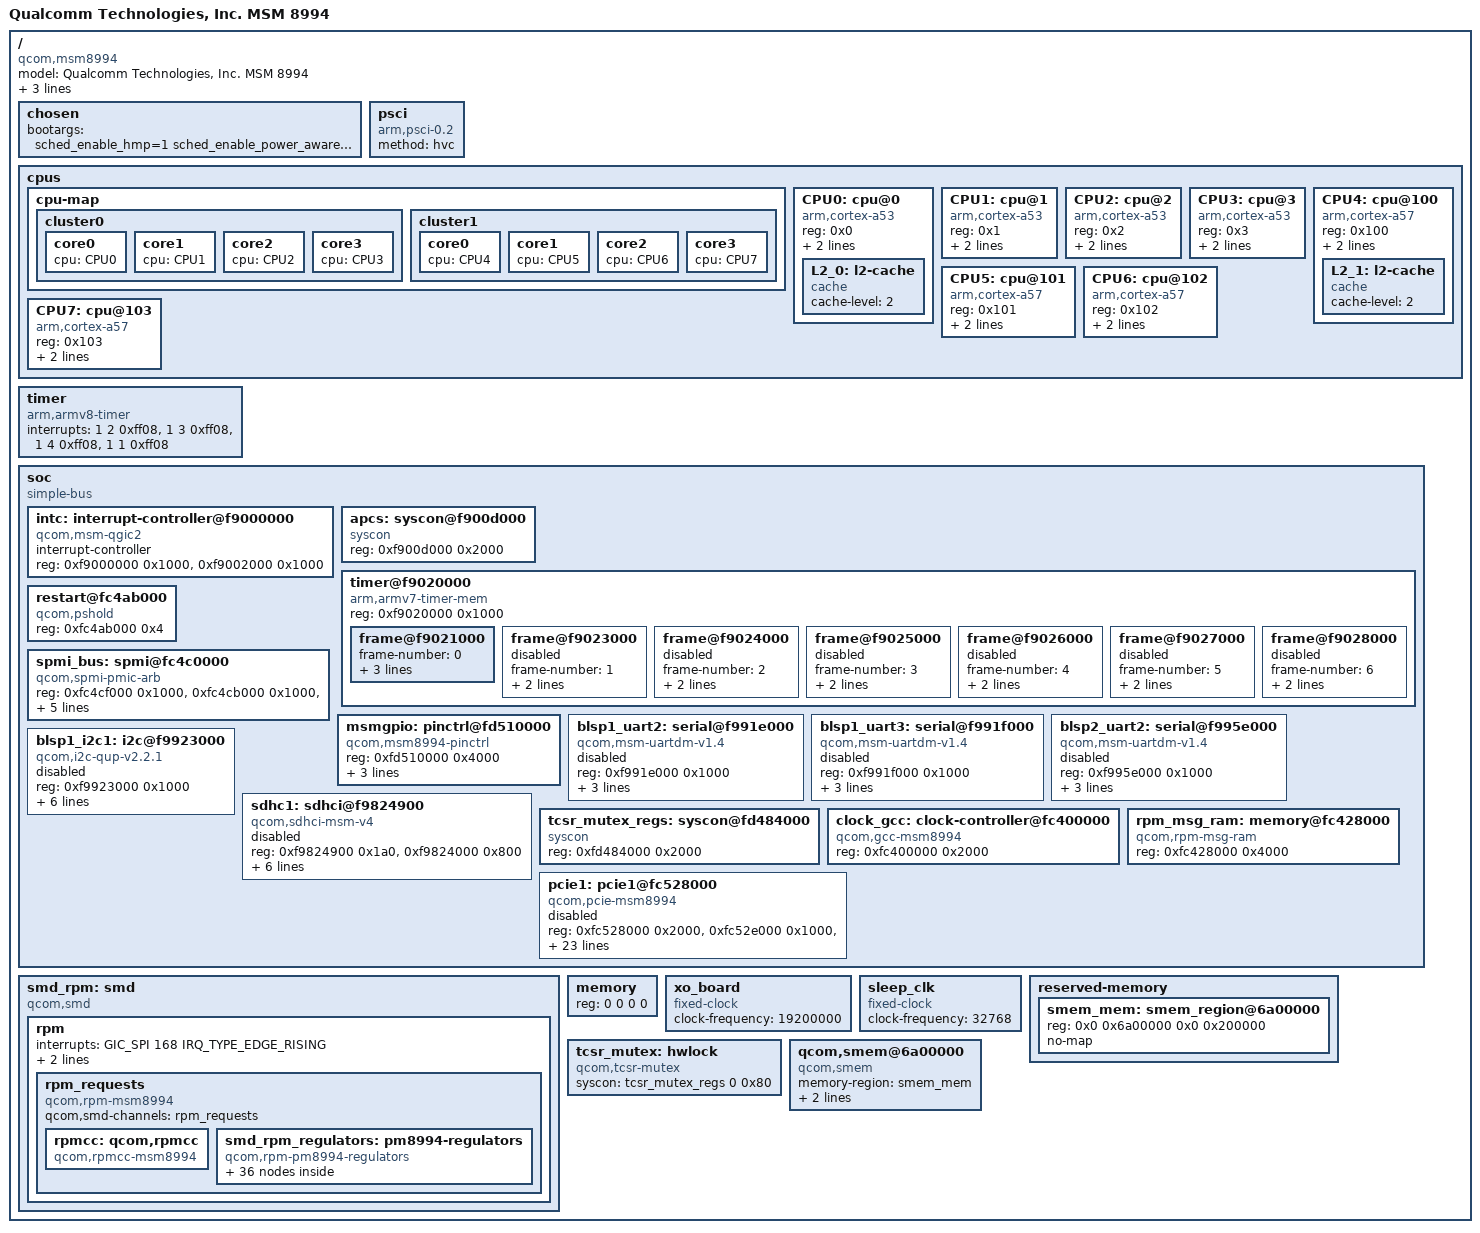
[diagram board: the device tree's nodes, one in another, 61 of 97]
/* Copyright (c) 2013-2016, The Linux Foundation. All rights reserved.
 *
 * This program is free software; you can redistribute it and/or modify
 * it under the terms of the GNU General Public License version 2 and
 * only version 2 as published by the Free Software Foundation.
 *
 * This program is distributed in the hope that it will be useful,
 * but WITHOUT ANY WARRANTY; without even the implied warranty of
 * MERCHANTABILITY or FITNESS FOR A PARTICULAR PURPOSE.  See the
 * GNU General Public License for more details.
 */

#include <dt-bindings/interrupt-controller/arm-gic.h>
#include <dt-bindings/clock/qcom,gcc-msm8994.h>
#include <dt-bindings/clock/qcom,rpmcc.h>

/ {
	model = "Qualcomm Technologies, Inc. MSM 8994";
	compatible = "qcom,msm8994";
	// msm-id and pmic-id are required by bootloader for
	// proper selection of dt blob
	qcom,msm-id = <207 0x20000>;
	qcom,pmic-id = <0x10009 0x1000A 0x0 0x0>;
	interrupt-parent = <&intc>;

	#address-cells = <2>;
	#size-cells = <2>;

	chosen {
		bootargs = "sched_enable_hmp=1 sched_enable_power_aware=1";
	};

	psci {
		compatible	= "arm,psci-0.2";
		method		= "hvc";
	};

	cpus {
		#address-cells = <1>;
		#size-cells = <0>;
		cpu-map {
			cluster0 {
				core0 {
					cpu = <&CPU0>;
				};
				core1 {
					cpu = <&CPU1>;
				};
				core2 {
					cpu = <&CPU2>;
				};
				core3 {
					cpu = <&CPU3>;
				};
			};
			cluster1 {
				core0 {
					cpu = <&CPU4>;
				};
				core1 {
					cpu = <&CPU5>;
				};
				core2 {
					cpu = <&CPU6>;
				};
				core3 {
					cpu = <&CPU7>;
				};
			};
		};

		CPU0: cpu@0 {
			device_type = "cpu";
			compatible = "arm,cortex-a53";
			reg = <0x0>;
			enable-method = "psci";
			next-level-cache = <&L2_0>;
			L2_0: l2-cache {
				compatible = "cache";
				cache-level = <2>;
			};
		};
		CPU1: cpu@1 {
			device_type = "cpu";
			compatible = "arm,cortex-a53";
			reg = <0x1>;
			enable-method = "psci";
			next-level-cache = <&L2_0>;
		};
		CPU2: cpu@2 {
			device_type = "cpu";
			compatible = "arm,cortex-a53";
			reg = <0x2>;
			enable-method = "psci";
			next-level-cache = <&L2_0>;
		};
		CPU3: cpu@3 {
			device_type = "cpu";
			compatible = "arm,cortex-a53";
			reg = <0x3>;
			enable-method = "psci";
			next-level-cache = <&L2_0>;
		};
		CPU4: cpu@100 {
			device_type = "cpu";
			compatible = "arm,cortex-a57";
			reg = <0x100>;
			enable-method = "psci";
			next-level-cache = <&L2_1>;
			L2_1: l2-cache {
				compatible = "cache";
				cache-level = <2>;
			};
		};
		CPU5: cpu@101 {
			device_type = "cpu";
			compatible = "arm,cortex-a57";
			reg = <0x101>;
			enable-method = "psci";
			next-level-cache = <&L2_1>;
		};
		CPU6: cpu@102 {
			device_type = "cpu";
			compatible = "arm,cortex-a57";
			reg = <0x102>;
			enable-method = "psci";
			next-level-cache = <&L2_1>;
		};
		CPU7: cpu@103 {
			device_type = "cpu";
			compatible = "arm,cortex-a57";
			reg = <0x103>;
			enable-method = "psci";
			next-level-cache = <&L2_1>;
		};
	};

	timer {
		compatible = "arm,armv8-timer";
		interrupts = <1 2 0xff08>,
			     <1 3 0xff08>,
			     <1 4 0xff08>,
			     <1 1 0xff08>;
	};

	soc: soc {

		#address-cells = <1>;
		#size-cells = <1>;
		ranges = <0 0 0 0xffffffff>;
		compatible = "simple-bus";

		intc: interrupt-controller@f9000000 {
			compatible = "qcom,msm-qgic2";
			interrupt-controller;
			#interrupt-cells = <3>;
			reg = <0xf9000000 0x1000>,
				  <0xf9002000 0x1000>;
		};

		apcs: syscon@f900d000 {
			compatible = "syscon";
			reg = <0xf900d000 0x2000>;
		};

		timer@f9020000 {
			#address-cells = <1>;
			#size-cells = <1>;
			ranges;
			compatible = "arm,armv7-timer-mem";
			reg = <0xf9020000 0x1000>;

			frame@f9021000 {
				frame-number = <0>;
				interrupts = <GIC_SPI 9 IRQ_TYPE_LEVEL_HIGH>,
					     <GIC_SPI 8 IRQ_TYPE_LEVEL_HIGH>;
				reg = <0xf9021000 0x1000>,
				      <0xf9022000 0x1000>;
			};

			frame@f9023000 {
				frame-number = <1>;
				interrupts = <GIC_SPI 10 IRQ_TYPE_LEVEL_HIGH>;
				reg = <0xf9023000 0x1000>;
				status = "disabled";
			};

			frame@f9024000 {
				frame-number = <2>;
				interrupts = <GIC_SPI 11 IRQ_TYPE_LEVEL_HIGH>;
				reg = <0xf9024000 0x1000>;
				status = "disabled";
			};

			frame@f9025000 {
				frame-number = <3>;
				interrupts = <GIC_SPI 12 IRQ_TYPE_LEVEL_HIGH>;
				reg = <0xf9025000 0x1000>;
				status = "disabled";
			};

			frame@f9026000 {
				frame-number = <4>;
				interrupts = <GIC_SPI 13 IRQ_TYPE_LEVEL_HIGH>;
				reg = <0xf9026000 0x1000>;
				status = "disabled";
			};

			frame@f9027000 {
				frame-number = <5>;
				interrupts = <GIC_SPI 14 IRQ_TYPE_LEVEL_HIGH>;
				reg = <0xf9027000 0x1000>;
				status = "disabled";
			};

			frame@f9028000 {
				frame-number = <6>;
				interrupts = <GIC_SPI 15 IRQ_TYPE_LEVEL_HIGH>;
				reg = <0xf9028000 0x1000>;
				status = "disabled";
			};
		};

		restart@fc4ab000 {
			compatible = "qcom,pshold";
			reg = <0xfc4ab000 0x4>;
		};

		spmi_bus: spmi@fc4c0000 {
			compatible = "qcom,spmi-pmic-arb";
			reg-names = "core", "intr", "cnfg";
			reg = <0xfc4cf000 0x1000>,
				<0xfc4cb000 0x1000>,
				<0xfc4ca000 0x1000>;

			interrupt-names = "periph_irq";
			interrupts = <GIC_SPI 190 IRQ_TYPE_LEVEL_HIGH>;

			qcom,ee = <0>;
			qcom,channel = <0>;

			#address-cells = <2>;
			#size-cells = <0>;

			interrupt-controller;
			#interrupt-cells = <4>;
		};

		msmgpio: pinctrl@fd510000 {
			compatible = "qcom,msm8994-pinctrl";
			reg = <0xfd510000 0x4000>;
			interrupts = <GIC_SPI 208 IRQ_TYPE_LEVEL_HIGH>;
			gpio-controller;
			#gpio-cells = <2>;
			interrupt-controller;
			#interrupt-cells = <2>;
		};

		blsp1_uart2: serial@f991e000 {
			compatible = "qcom,msm-uartdm-v1.4", "qcom,msm-uartdm";
			reg = <0xf991e000 0x1000>;
			interrupts = <GIC_SPI 108 IRQ_TYPE_LEVEL_HIGH>;
			status = "disabled";
			clock-names = "core", "iface";
			clocks = <&clock_gcc GCC_BLSP1_UART2_APPS_CLK>,
				 <&clock_gcc GCC_BLSP1_AHB_CLK>;
		};

		blsp1_uart3: serial@f991f000 {
			compatible = "qcom,msm-uartdm-v1.4", "qcom,msm-uartdm";
			reg = <0xf991f000 0x1000>;
			interrupts = <GIC_SPI 109 IRQ_TYPE_LEVEL_HIGH>;
			status = "disabled";
			clock-names = "core", "iface";
			clocks = <&clock_gcc GCC_BLSP1_UART3_APPS_CLK>,
				 <&clock_gcc GCC_BLSP1_AHB_CLK>;
		};

		blsp2_uart2: serial@f995e000 {
			compatible = "qcom,msm-uartdm-v1.4", "qcom,msm-uartdm";
			reg = <0xf995e000 0x1000>;
			interrupts = <GIC_SPI 114 IRQ_TYPE_LEVEL_HIGH>;
			status = "disabled";
			clock-names = "core", "iface";
			clocks = <&clock_gcc GCC_BLSP2_UART2_APPS_CLK>,
				 <&clock_gcc GCC_BLSP2_AHB_CLK>;
		};

		blsp1_i2c1: i2c@f9923000 {
			compatible = "qcom,i2c-qup-v2.2.1";
			reg = <0xf9923000 0x1000>;
			interrupts = <GIC_SPI 95 IRQ_TYPE_LEVEL_HIGH>;
			clocks = <&clock_gcc GCC_BLSP1_AHB_CLK>,
				 <&clock_gcc GCC_BLSP1_QUP1_I2C_APPS_CLK>;
			clock-names = "iface", "core";
			pinctrl-names = "default", "sleep";
			pinctrl-0 = <&i2c1_default>;
			pinctrl-1 = <&i2c1_sleep>;
			clock-frequency = <400000>;
			#address-cells = <1>;
			#size-cells = <0>;
			status = "disabled";
		};

		sdhc1: sdhci@f9824900 {
			status = "disabled";
			compatible = "qcom,sdhci-msm-v4";
			reg = <0xf9824900 0x1a0>, <0xf9824000 0x800>;
			reg-names = "hc_mem", "core_mem";

			interrupts = <0 123 IRQ_TYPE_LEVEL_HIGH>,
				      <0 138 IRQ_TYPE_LEVEL_HIGH>;
			interrupt-names = "hc_irq", "pwr_irq";

			clock-names = "iface", "core", "xo";
			clocks = <&clock_gcc GCC_SDCC1_AHB_CLK>,
			<&clock_gcc GCC_SDCC1_APPS_CLK>,
			<&xo_board>;
			bus-width = <4>;
			non-removable;
		};

		tcsr_mutex_regs: syscon@fd484000 {
			compatible = "syscon";
			reg = <0xfd484000 0x2000>;
		};

		clock_gcc: clock-controller@fc400000 {
			compatible = "qcom,gcc-msm8994";
			#clock-cells = <1>;
			#reset-cells = <1>;
			#power-domain-cells = <1>;
			reg = <0xfc400000 0x2000>;
		};

		rpm_msg_ram: memory@fc428000 {
			compatible = "qcom,rpm-msg-ram";
			reg = <0xfc428000 0x4000>;
		};

		pcie1: pcie1@fc528000 {
			compatible = "qcom,pcie-msm8994", "snps,dc-pcie";
			reg = <0xfc528000 0x2000>,
				<0xfc52e000 0x1000>,
				<0xf8800000 0xf1d>,
				<0xf8800f20 0xa8>,
		    	<0xf8801000 0x7f000>;
			reg-names = "parf", "altphy", "dbi", "elbi","config";

			bus-range = <0x00 0xff>;
			num-lanes = <1>;

			#address-cells = <3>;
			#size-cells = <2>;
			ranges = <0x01000000 0x0 0xf8880000 0xf8880000 0x0 0x80000>,
				<0x02000000 0x0 0xf8900000 0xf8900000 0x0 0x700000>;
			interrupts = <GIC_SPI 271 IRQ_TYPE_LEVEL_HIGH>;
			interrupt-names = "msi";
			#interrupt-cells = <1>;
			interrupt-map-mask = <0 0 0 0x7>;
			interrupt-map = <0 0 0 1 &intc 0 272 IRQ_TYPE_LEVEL_HIGH>, /* int_a */
					<0 0 0 2 &intc 0 273 IRQ_TYPE_LEVEL_HIGH>, /* int_b */
					<0 0 0 3 &intc 0 274 IRQ_TYPE_LEVEL_HIGH>, /* int_c */
					<0 0 0 4 &intc 0 275 IRQ_TYPE_LEVEL_HIGH>; /* int_d */

			pinctrl-names = "default";
			pinctrl-0 = <&pcie1_clkreq_default &pcie1_perst_default &pcie1_wake_default>;

			vdda-phy-supply = <&pm8994_l28>;
			vdda-pll-supply = <&pm8994_l12>;

			linux,pci-domain = <1>;

			clocks = <&clock_gcc GCC_PCIE_1_PIPE_CLK>,
				<&rpmcc RPM_SMD_LN_BB_CLK>,
				<&clock_gcc GCC_PCIE_1_AUX_CLK>,
				<&clock_gcc GCC_PCIE_1_CFG_AHB_CLK>,
				<&clock_gcc GCC_PCIE_1_MSTR_AXI_CLK>,
				<&clock_gcc GCC_PCIE_1_PHY_LDO_EN_CLK>;

			clock-names = "pipe_clk",
				"ref_clk_src",
				"aux_clk",
				"cfg_ahb_clk",
				"mstr_axi_clk",
				"phy_ldo_clk";

			resets = <&clock_gcc GCC_PCIE_PHY_1_PHY_BCR>;
			reset-names = "phy_reset";
			status = "disabled";
		};
	};

	smd_rpm: smd {
		compatible = "qcom,smd";
		rpm {
			interrupts = <GIC_SPI 168 IRQ_TYPE_EDGE_RISING>;
			qcom,ipc = <&apcs 8 0>;
			qcom,smd-edge = <15>;
			
			rpm_requests {
				compatible = "qcom,rpm-msm8994";
				qcom,smd-channels = "rpm_requests";

				rpmcc: qcom,rpmcc {
					compatible = "qcom,rpmcc-msm8994";
					#clock-cells = <1>;
				};

				smd_rpm_regulators: pm8994-regulators {
					compatible = "qcom,rpm-pm8994-regulators";

					pm8994_s1: s1 {};
					pm8994_s2: s2 {};
					pm8994_s3: s3 {};
					pm8994_s4: s4 {};
					pm8994_s5: s5 {};
					pm8994_s7: s7 {};

					pm8994_l1: l1 {};
					pm8994_l2: l2 {};
					pm8994_l3: l3 {};
					pm8994_l4: l4 {};
					pm8994_l6: l6 {};
					pm8994_l8: l8 {};
					pm8994_l9: l9 {};
					pm8994_l10: l10 {};
					pm8994_l11: l11 {};
					pm8994_l12: l12 {};
					pm8994_l13: l13 {};
					pm8994_l14: l14 {};
					pm8994_l15: l15 {};
					pm8994_l16: l16 {};
					pm8994_l17: l17 {};
					pm8994_l18: l18 {};
					pm8994_l19: l19 {};
					pm8994_l20: l20 {};
					pm8994_l21: l21 {};
					pm8994_l22: l22 {};
					pm8994_l23: l23 {};
					pm8994_l24: l24 {};
					pm8994_l25: l25 {};
					pm8994_l26: l26 {};
					pm8994_l27: l27 {};
					pm8994_l28: l28 {};
					pm8994_l29: l29 {};
					pm8994_l30: l30 {};
					pm8994_l31: l31 {};
					pm8994_l32: l32 {};
				};
			};
		};
	};

	memory {
		device_type = "memory";
		// We expect the bootloader to fill in the reg
		reg = <0 0 0 0>;
	};

	xo_board: xo_board {
		compatible = "fixed-clock";
		#clock-cells = <0>;
		clock-frequency = <19200000>;
	};

	sleep_clk: sleep_clk {
		compatible = "fixed-clock";
		#clock-cells = <0>;
		clock-frequency = <32768>;
	};

	reserved-memory {
		#address-cells = <2>;
		#size-cells = <2>;
		ranges;

		smem_mem: smem_region@6a00000 {
			reg = <0x0 0x6a00000 0x0 0x200000>;
			no-map;
		};
	};

	tcsr_mutex: hwlock {
		compatible = "qcom,tcsr-mutex";
		syscon = <&tcsr_mutex_regs 0 0x80>;
		#hwlock-cells = <1>;
	};

	qcom,smem@6a00000 {
		compatible = "qcom,smem";
		memory-region = <&smem_mem>;
		hwlocks = <&tcsr_mutex 3>;
		qcom,rpm-msg-ram = <&rpm_msg_ram>;
	};
};


#include "msm8994-pins.dtsi"
